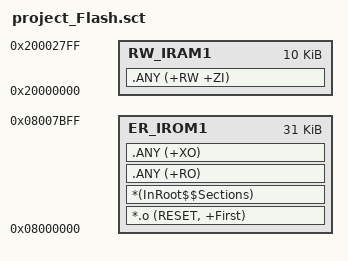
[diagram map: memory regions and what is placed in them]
; ***********************************************************************
; *** Scatter-Loading Description File generated by uv2csolution ***
; ***********************************************************************

LR_IROM1 0x08000000 0x00007c00 {    ; load region size_region (0x7c00 so that we have 0x400 bytes of flash for storing prefs)
  ER_IROM1 0x08000000 0x00007c00 {  ; load address = execution address
   *.o (RESET, +First)
   *(InRoot$$Sections)
   .ANY (+RO)
   .ANY (+XO)
  }
  RW_IRAM1 0x20000000 0x00002800 {  ; RW data
   .ANY (+RW +ZI)
  }
}

